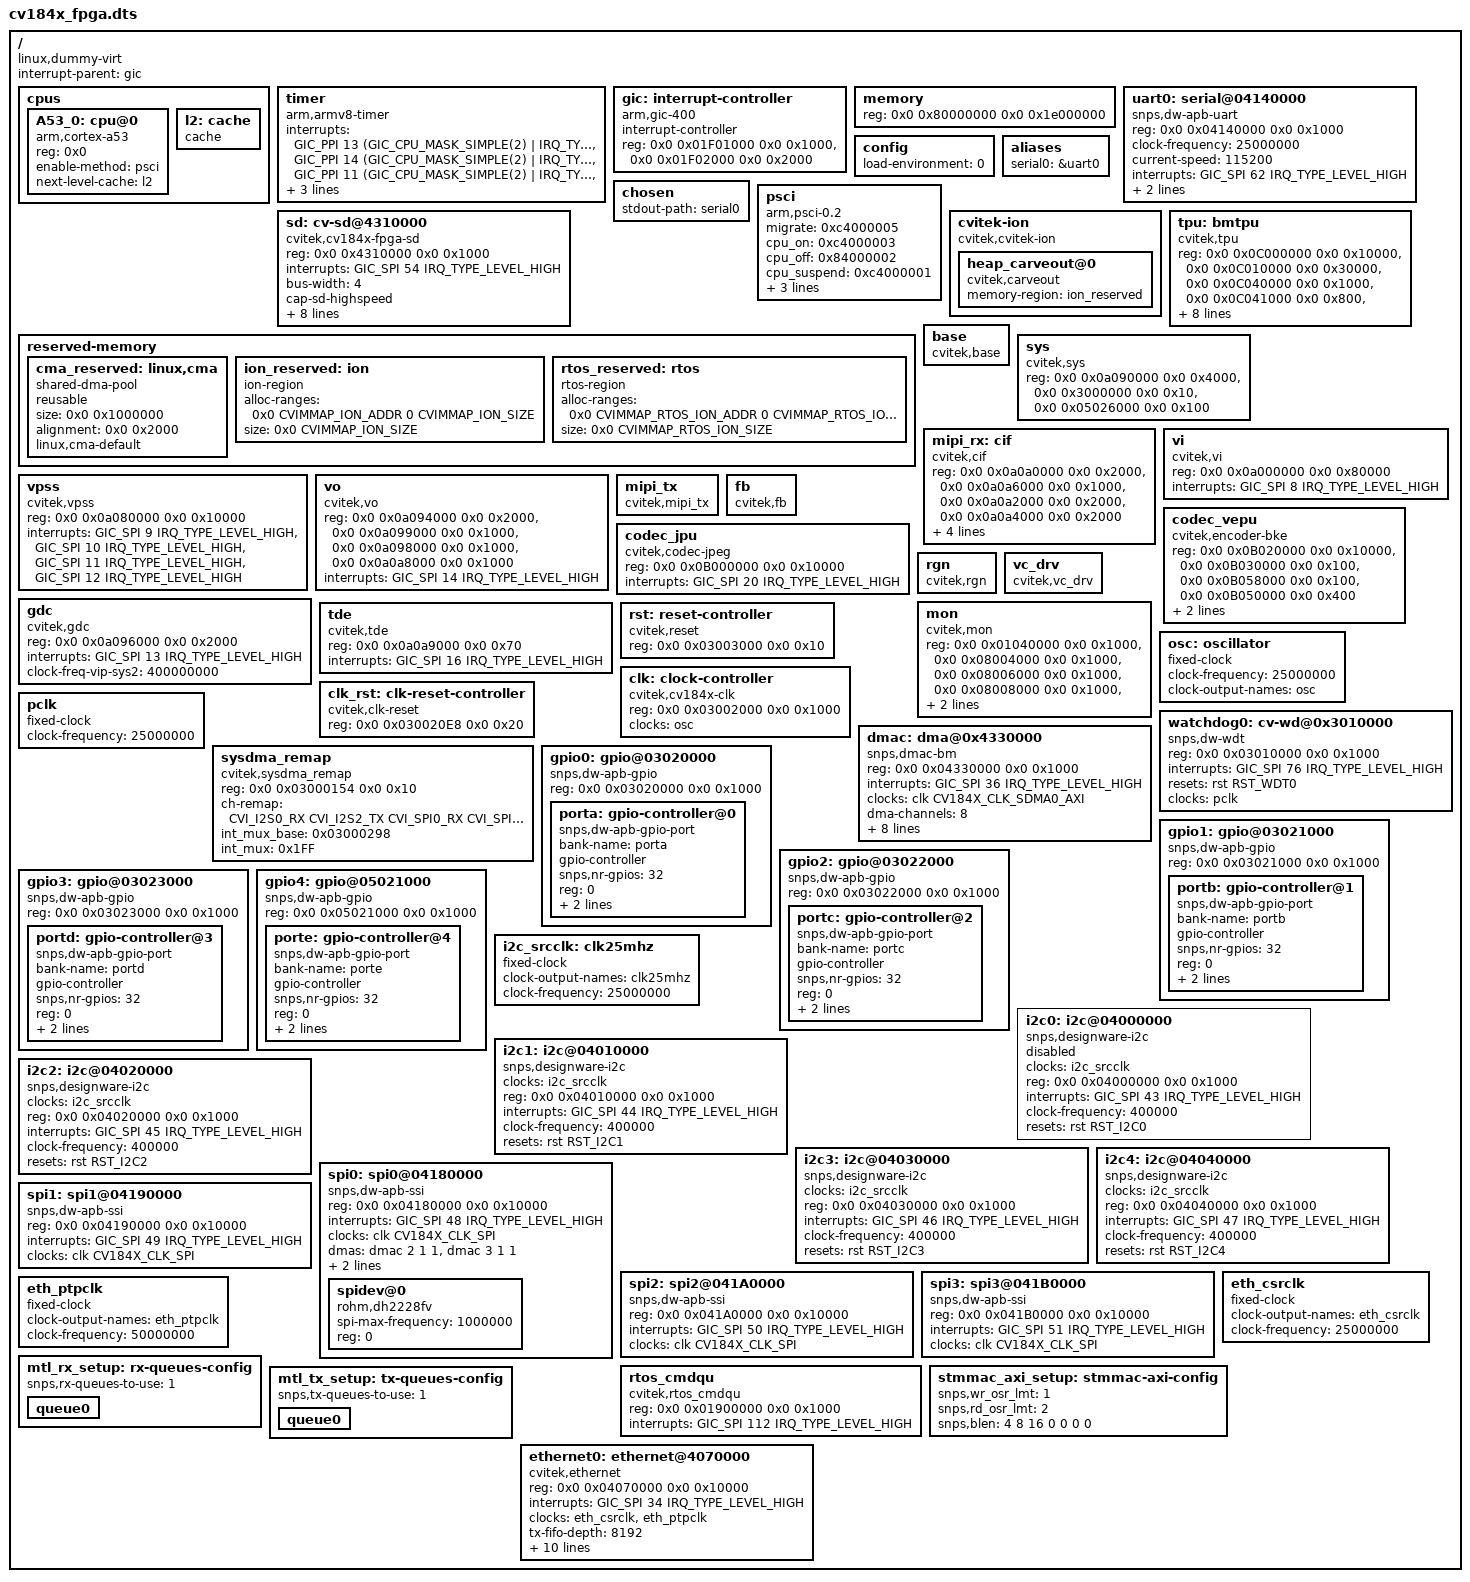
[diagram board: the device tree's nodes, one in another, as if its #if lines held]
#include <dt-bindings/interrupt-controller/arm-gic.h>
#include <dt-bindings/gpio/gpio.h>
#include <dt-bindings/reset/cv184x-resets.h>
#include <dt-bindings/clock/cv184x-clock.h>
//#include <dt-bindings/sound/cv1835-audio.h>
#include <dt-bindings/dma/cv184x-dmamap.h>
#include "cvi_board_memmap.h"
/dts-v1/;

/memreserve/	0x80000000 0x00000000000080000; // ATF BL31 + BL32
#if CVIMMAP_RTOS_SYS_TOTAL_SIZE > 0
/memreserve/	CVIMMAP_FSBL_C906L_START_ADDR CVIMMAP_RTOS_SYS_TOTAL_SIZE;
#endif
/ {
	compatible = "linux,dummy-virt";
	#size-cells = <0x2>;
	#address-cells = <0x2>;
	interrupt-parent = <&gic>;

	cpus {
		#size-cells = <0x0>;
		#address-cells = <0x1>;

		A53_0: cpu@0 {
			reg = <0x0>;
			enable-method = "psci";
			compatible = "arm,cortex-a53";
			device_type = "cpu";
			next-level-cache = <&l2>;
		};

		l2: cache {
			compatible = "cache";
		};
	};

	timer {
		interrupts = <GIC_PPI 13 (GIC_CPU_MASK_SIMPLE(2) | IRQ_TYPE_LEVEL_LOW)>,
			<GIC_PPI 14 (GIC_CPU_MASK_SIMPLE(2) | IRQ_TYPE_LEVEL_LOW)>,
			<GIC_PPI 11 (GIC_CPU_MASK_SIMPLE(2) | IRQ_TYPE_LEVEL_LOW)>,
			<GIC_PPI 10 (GIC_CPU_MASK_SIMPLE(2) | IRQ_TYPE_LEVEL_LOW)>;
		always-on;
		clock-frequency = <25000000>;
		compatible = "arm,armv8-timer";
	};

	gic: interrupt-controller {
		compatible = "arm,gic-400";
		ranges;
		#size-cells = <0x2>;
		#address-cells = <0x2>;
		interrupt-controller;
		#interrupt-cells = <0x3>;
		reg = <0x0 0x01F01000 0x0 0x1000>,
		      <0x0 0x01F02000 0x0 0x2000>;
	};

	memory {
		reg = <0x0 0x80000000 0x0 0x1e000000>;
		device_type = "memory";
	};

	uart0: serial@04140000 {
		compatible = "snps,dw-apb-uart";
		reg = <0x0 0x04140000 0x0 0x1000>;
		clock-frequency = <25000000>;
		current-speed = <115200>;
		interrupts = <GIC_SPI 62 IRQ_TYPE_LEVEL_HIGH>;
		reg-shift = <2>;
		reg-io-width = <4>;
	};

	config {
		load-environment = <0>;
	};

	aliases {
		serial0 = &uart0;
	};

	chosen {
		stdout-path = "serial0"; // "serial0:115200n8", no arguments means no re-initialization
	};

	psci {
		migrate = <0xc4000005>;
		cpu_on = <0xc4000003>;
		cpu_off = <0x84000002>;
		cpu_suspend = <0xc4000001>;
		sys_poweroff = <0x84000008>;
		sys_reset = <0x84000009>;
		method = "smc";
		compatible = "arm,psci-0.2", "arm,psci";
	};

	sd:cv-sd@4310000 {
		compatible = "cvitek,cv184x-fpga-sd";
		reg = <0x0 0x4310000 0x0 0x1000>;
		reg-names = "core_mem";
		interrupts = <GIC_SPI 54 IRQ_TYPE_LEVEL_HIGH>;
		bus-width = <4>;
		cap-sd-highspeed;
		src-frequency = <25000000>;
		min-frequency = <200000>;
		max-frequency = <4000000>;
		no-sdio;
		no-mmc;
		no-1-8-v;
		64_addressing;
		reset_tx_rx_phy;
		reset-names = "sdhci";
	};

	cvitek-ion {
		compatible = "cvitek,cvitek-ion";

		heap_carveout@0 {
			compatible = "cvitek,carveout";
			memory-region = <&ion_reserved>;
		};
	};

	reserved-memory {
		#address-cells = <0x2>;
		#size-cells = <0x2>;
		ranges;

		cma_reserved: linux,cma {
			compatible = "shared-dma-pool";
			reusable;
			size = <0x0 0x1000000>; // 16MB
			alignment = <0x0 0x2000>; // 8KB
			linux,cma-default;
		};

		ion_reserved: ion {
			compatible = "ion-region";
			alloc-ranges = <0x0 CVIMMAP_ION_ADDR 0 CVIMMAP_ION_SIZE>;
			size = <0x0 CVIMMAP_ION_SIZE>;
		};
#if CVIMMAP_RTOS_SYS_TOTAL_SIZE > 0
		rtos_reserved: rtos {
			compatible = "rtos-region";
			alloc-ranges = <0x0 CVIMMAP_RTOS_ION_ADDR 0 CVIMMAP_RTOS_ION_SIZE>;
			size = <0x0 CVIMMAP_RTOS_ION_SIZE>;
		};
#endif
	};


	tpu: bmtpu {
		compatible = "cvitek,tpu";
		reg-names = "tpu_gdma", "tpu_sys","tpu_reg","tpu_smem","tpu_lmem";
		reg = <0x0 0x0C000000 0x0 0x10000>,
			<0x0 0x0C010000 0x0 0x30000>,
			<0x0 0x0C040000 0x0 0x1000>,
			<0x0 0x0C041000 0x0 0x800>,
			<0x0 0x0C080000 0x0 0x8000>;
		interrupts = <GIC_SPI 89 IRQ_TYPE_LEVEL_HIGH>,
			<GIC_SPI 90 IRQ_TYPE_LEVEL_HIGH>,
			<GIC_SPI 91 IRQ_TYPE_LEVEL_HIGH>,
			<GIC_SPI 92 IRQ_TYPE_LEVEL_HIGH>,
			<GIC_SPI 93 IRQ_TYPE_LEVEL_HIGH>,
			<GIC_SPI 94 IRQ_TYPE_LEVEL_HIGH>,
			<GIC_SPI 95 IRQ_TYPE_LEVEL_HIGH>;
	};

	base {
		compatible = "cvitek,base";
	};

	sys {
		compatible = "cvitek,sys";
		reg = <0x0 0x0a090000 0x0 0x4000>,
				<0x0 0x3000000 0x0 0x10>,
				<0x0 0x05026000 0x0 0x100>;
		reg-names = "vi_sys", "top_base", "rtc_base";
	};

	mipi_rx: cif {
		compatible = "cvitek,cif";
		reg = <0x0 0x0a0a0000 0x0 0x2000>, <0x0 0x0a0a6000 0x0 0x1000>,
		      <0x0 0x0a0a2000 0x0 0x2000>, <0x0 0x0a0a4000 0x0 0x2000>;
		reg-names = "csi_mac0", "csi_wrap0", "csi_mac1", "csi_mac2";
		interrupts = <GIC_SPI 5 IRQ_TYPE_LEVEL_HIGH>,
			     <GIC_SPI 6 IRQ_TYPE_LEVEL_HIGH>, <GIC_SPI 7 IRQ_TYPE_LEVEL_HIGH>;
		interrupt-names = "csi0", "csi1", "csi2";
		snsr-reset = <&porta 2 GPIO_ACTIVE_LOW>;
	};

	vi {
		compatible = "cvitek,vi";
		reg = <0x0 0x0a000000 0x0 0x80000>;
		interrupts = <GIC_SPI 8 IRQ_TYPE_LEVEL_HIGH>;
		interrupt-names = "isp";
	};

	vpss {
		compatible = "cvitek,vpss";
		reg = <0x0 0x0a080000 0x0 0x10000>;
		reg-names = "vpss";
		interrupts = <GIC_SPI 9 IRQ_TYPE_LEVEL_HIGH>,
					<GIC_SPI 10 IRQ_TYPE_LEVEL_HIGH>,
					<GIC_SPI 11 IRQ_TYPE_LEVEL_HIGH>,
					<GIC_SPI 12 IRQ_TYPE_LEVEL_HIGH>;
		interrupt-names = "vpss_v0","vpss_v1","vpss_v2","vpss_v3";
	};

	vo {
		compatible = "cvitek,vo";
		reg =   <0x0 0x0a094000 0x0 0x2000>,
			<0x0 0x0a099000 0x0 0x1000>,
			<0x0 0x0a098000 0x0 0x1000>,
			<0x0 0x0a0a8000 0x0 0x1000>;
		reg-names = "disp", "dsi_mac", "dsi_phy", "vo_mac";

		interrupts = <GIC_SPI 14 IRQ_TYPE_LEVEL_HIGH>;
		interrupt-names = "disp";
	};

	mipi_tx {
		compatible = "cvitek,mipi_tx";
	};

	fb {
		compatible = "cvitek,fb";
	};

	codec_vepu {
		compatible = "cvitek,encoder-bke";
		reg = <0x0 0x0B020000 0x0 0x10000>,<0x0 0x0B030000 0x0 0x100>,
				<0x0 0x0B058000 0x0 0x100>,<0x0 0x0B050000 0x0 0x400>;
		reg-names = "vepu","vc_ctrl","vc_sbm","vc_addr_remap";
		interrupts = <GIC_SPI 19 IRQ_TYPE_LEVEL_HIGH>,
					<GIC_SPI 21 IRQ_TYPE_LEVEL_HIGH>;
		interrupt-names = "vepu_irq","sbm_irq";
	};

	codec_jpu {
		compatible = "cvitek,codec-jpeg";
		reg = <0x0 0x0B000000 0x0 0x10000>;
		reg-names = "jpeg_ctrl";
		interrupts = <GIC_SPI 20 IRQ_TYPE_LEVEL_HIGH>;
		interrupt-names = "jpeg_irq";
	};

	rgn {
		compatible = "cvitek,rgn";
	};

	vc_drv {
		compatible = "cvitek,vc_drv";
	};

	gdc {
		compatible = "cvitek,gdc";
		reg = <0x0 0x0a096000 0x0 0x2000>;
		reg-names = "ldc0";
		interrupts = <GIC_SPI 13 IRQ_TYPE_LEVEL_HIGH>;
		interrupt-names = "ldc0";
		clock-names = "clk_ldc0";
		clock-freq-vip-sys2 = <400000000>;
	};

	tde {
		compatible = "cvitek,tde";
		reg = <0x0 0x0a0a9000 0x0 0x70>;
		reg-names = "tde";
		interrupts = <GIC_SPI 16 IRQ_TYPE_LEVEL_HIGH>;
		interrupt-names = "tde";
	};


	mon {
		compatible = "cvitek,mon";
		reg-names = "pcmon", "ddr_ctrl", "ddr_phyd", "ddr_aximon", "ddr_top";
		reg = <0x0 0x01040000 0x0 0x1000>,
		    <0x0 0x08004000 0x0 0x1000>,
			<0x0 0x08006000 0x0 0x1000>,
			<0x0 0x08008000 0x0 0x1000>,
			<0x0 0x0800A000 0x0 0x1000>;
		interrupts = <GIC_SPI 22 IRQ_TYPE_EDGE_RISING>;
	};


	rst: reset-controller {
		#reset-cells = <1>;
		compatible = "cvitek,reset";
		reg = <0x0 0x03003000 0x0 0x10>;
	};

	osc: oscillator {
		#clock-cells = <0>;
		compatible = "fixed-clock";
		clock-frequency = <25000000>;
		clock-output-names = "osc";
	};

	clk: clock-controller {
		compatible = "cvitek,cv184x-clk";
		reg = <0x0 0x03002000 0x0 0x1000>;
		clocks = <&osc>;
		#clock-cells = <1>;
	};

	clk_rst: clk-reset-controller {
		#reset-cells = <1>;
		compatible = "cvitek,clk-reset";
		reg = <0x0 0x030020E8 0x0 0x20>;
	};

	pclk: pclk {
		#clock-cells = <0>;
		compatible = "fixed-clock";
		clock-frequency = <25000000>;
	};

	watchdog0: cv-wd@0x3010000 {
		compatible = "snps,dw-wdt";
		reg = <0x0 0x03010000 0x0 0x1000>;
		interrupts = <GIC_SPI 76 IRQ_TYPE_LEVEL_HIGH>;
		resets = <&rst RST_WDT0>;
		clocks = <&pclk>;
	};

	sysdma_remap {
		compatible = "cvitek,sysdma_remap";
		reg = <0x0 0x03000154 0x0 0x10>;
		ch-remap = <CVI_I2S0_RX CVI_I2S2_TX CVI_SPI0_RX CVI_SPI0_TX
					CVI_SPI_NAND CVI_SPI_NAND CVI_I2S2_RX CVI_I2S3_TX>;
		int_mux_base = <0x03000298>;
		int_mux = <0x1FF>; /* enable bit [0..8] for CPU0(CA53) */
	};

	dmac: dma@0x4330000 {
		compatible = "snps,dmac-bm";
		reg = <0x0 0x04330000 0x0 0x1000>;
		interrupts = <GIC_SPI 36 IRQ_TYPE_LEVEL_HIGH>;
		clock-names = "clk_sdma0_axi";
		clocks = <&clk CV184X_CLK_SDMA0_AXI>;

		dma-channels = /bits/ 8 <8>;
		#dma-cells = <3>;
		dma-requests = /bits/ 8 <16>;
		chan_allocation_order = /bits/ 8 <0>;
		chan_priority = /bits/ 8 <1>;
		block_size = <1024>;
		dma-masters = /bits/ 8 <2>;
		data-width = <4 4>; /* bytes */
		axi_tr_width = <4>; /* bytes */
		block-ts = <15>;
	};

	gpio0: gpio@03020000 {
		compatible = "snps,dw-apb-gpio";
		reg = <0x0 0x03020000 0x0 0x1000>;
		#address-cells = <1>;
		#size-cells = <0>;

		porta: gpio-controller@0 {
			compatible = "snps,dw-apb-gpio-port";
			bank-name = "porta";
			gpio-controller;
			#gpio-cells = <2>;
			snps,nr-gpios = <32>;
			reg = <0>;
			interrupt-controller;
			interrupts = <GIC_SPI 79 IRQ_TYPE_LEVEL_HIGH>;
		};
	};

	gpio1: gpio@03021000 {
		compatible = "snps,dw-apb-gpio";
		reg = <0x0 0x03021000 0x0 0x1000>;
		#address-cells = <1>;
		#size-cells = <0>;

		portb: gpio-controller@1 {
			compatible = "snps,dw-apb-gpio-port";
			bank-name = "portb";
			gpio-controller;
			#gpio-cells = <2>;
			snps,nr-gpios = <32>;
			reg = <0>;
			interrupt-controller;
			interrupts = <GIC_SPI 80 IRQ_TYPE_LEVEL_HIGH>;
		};
	};

	gpio2: gpio@03022000 {
		compatible = "snps,dw-apb-gpio";
		reg = <0x0 0x03022000 0x0 0x1000>;
		#address-cells = <1>;
		#size-cells = <0>;

		portc: gpio-controller@2 {
			compatible = "snps,dw-apb-gpio-port";
			bank-name = "portc";
			gpio-controller;
			#gpio-cells = <2>;
			snps,nr-gpios = <32>;
			reg = <0>;
			interrupt-controller;
			interrupts = <GIC_SPI 81 IRQ_TYPE_LEVEL_HIGH>;
		};
	};

	gpio3: gpio@03023000 {
		compatible = "snps,dw-apb-gpio";
		reg = <0x0 0x03023000 0x0 0x1000>;
		#address-cells = <1>;
		#size-cells = <0>;

		portd: gpio-controller@3 {
			compatible = "snps,dw-apb-gpio-port";
			bank-name = "portd";
			gpio-controller;
			#gpio-cells = <2>;
			snps,nr-gpios = <32>;
			reg = <0>;
			interrupt-controller;
			interrupts = <GIC_SPI 82 IRQ_TYPE_LEVEL_HIGH>;
		};
	};

	gpio4: gpio@05021000 {
		compatible = "snps,dw-apb-gpio";
		reg = <0x0 0x05021000 0x0 0x1000>;
		#address-cells = <1>;
		#size-cells = <0>;

		porte: gpio-controller@4 {
			compatible = "snps,dw-apb-gpio-port";
			bank-name = "porte";
			gpio-controller;
			#gpio-cells = <2>;
			snps,nr-gpios = <32>;
			reg = <0>;
			interrupt-controller;
			interrupts = <GIC_SPI 29 IRQ_TYPE_LEVEL_HIGH>;
		};
	};

	i2c_srcclk: clk25mhz {
		clock-output-names = "clk25mhz";
		clock-frequency = <25000000>;
		#clock-cells = <0x0>;
		compatible = "fixed-clock";
	};


	i2c0: i2c@04000000 {
		compatible = "snps,designware-i2c";
		clocks = <&i2c_srcclk>;
		reg = <0x0 0x04000000 0x0 0x1000>;
		interrupts = <GIC_SPI 43 IRQ_TYPE_LEVEL_HIGH>;
		clock-frequency = <400000>;

		#size-cells = <0x0>;
		#address-cells = <0x1>;
		resets = <&rst RST_I2C0>;
		reset-names = "i2c0";
		status = "disabled";
	};

	i2c1: i2c@04010000 {
		compatible = "snps,designware-i2c";
		clocks = <&i2c_srcclk>;
		reg = <0x0 0x04010000 0x0 0x1000>;
		interrupts = <GIC_SPI 44 IRQ_TYPE_LEVEL_HIGH>;
		clock-frequency = <400000>;

		#size-cells = <0x0>;
		#address-cells = <0x1>;
		resets = <&rst RST_I2C1>;
		reset-names = "i2c1";
	};

	i2c2: i2c@04020000 {
		compatible = "snps,designware-i2c";
		clocks = <&i2c_srcclk>;
		reg = <0x0 0x04020000 0x0 0x1000>;
		interrupts = <GIC_SPI 45 IRQ_TYPE_LEVEL_HIGH>;
		clock-frequency = <400000>;
		resets = <&rst RST_I2C2>;
		reset-names = "i2c2";
	};

	i2c3: i2c@04030000 {
		compatible = "snps,designware-i2c";
		clocks = <&i2c_srcclk>;
		reg = <0x0 0x04030000 0x0 0x1000>;
		interrupts = <GIC_SPI 46 IRQ_TYPE_LEVEL_HIGH>;
		clock-frequency = <400000>;

		#size-cells = <0x0>;
		#address-cells = <0x1>;
		resets = <&rst RST_I2C3>;
		reset-names = "i2c3";
	};

	i2c4: i2c@04040000 {
		compatible = "snps,designware-i2c";
		clocks = <&i2c_srcclk>;
		reg = <0x0 0x04040000 0x0 0x1000>;
		interrupts = <GIC_SPI 47 IRQ_TYPE_LEVEL_HIGH>;
		clock-frequency = <400000>;
		resets = <&rst RST_I2C4>;
		reset-names = "i2c4";
	};

	spi0:spi0@04180000 {
		compatible = "snps,dw-apb-ssi";
		reg = <0x0 0x04180000 0x0 0x10000>;
		interrupts = <GIC_SPI 48 IRQ_TYPE_LEVEL_HIGH>;
		clocks = <&clk CV184X_CLK_SPI>;
		#address-cells = <1>;
		#size-cells = <0>;
		dmas = <&dmac 2 1 1
			&dmac 3 1 1>;
		dma-names = "rx", "tx";
		capability = "txrx";
		status = "okay";
		num-cs = <1>;
		spidev@0 {
			compatible = "rohm,dh2228fv";
			spi-max-frequency = <1000000>;
			reg = <0>;
		};
	};

	spi1:spi1@04190000 {
		compatible = "snps,dw-apb-ssi";
		reg = <0x0 0x04190000 0x0 0x10000>;
		interrupts = <GIC_SPI 49 IRQ_TYPE_LEVEL_HIGH>;
		clocks = <&clk CV184X_CLK_SPI>;
		#address-cells = <1>;
		#size-cells = <0>;
	};

	spi2:spi2@041A0000 {
		compatible = "snps,dw-apb-ssi";
		reg = <0x0 0x041A0000 0x0 0x10000>;
		interrupts = <GIC_SPI 50 IRQ_TYPE_LEVEL_HIGH>;
		clocks = <&clk CV184X_CLK_SPI>;
		#address-cells = <1>;
		#size-cells = <0>;
	};

	spi3:spi3@041B0000 {
		compatible = "snps,dw-apb-ssi";
		reg = <0x0 0x041B0000 0x0 0x10000>;
		interrupts = <GIC_SPI 51 IRQ_TYPE_LEVEL_HIGH>;
		clocks = <&clk CV184X_CLK_SPI>;
		#address-cells = <1>;
		#size-cells = <0>;
	};
#if CVIMMAP_RTOS_SYS_TOTAL_SIZE > 0
	rtos_cmdqu {
		compatible = "cvitek,rtos_cmdqu";
		reg = <0x0 0x01900000 0x0 0x1000>;
		reg-names = "mailbox";
		interrupts = <GIC_SPI 112 IRQ_TYPE_LEVEL_HIGH>;
		interrupt-names = "mailbox";
	};
#endif



#if 0
	pmu_a53 {
		compatible = "arm,cortex-a53-pmu";
		interrupts = <GIC_SPI 86 IRQ_TYPE_LEVEL_HIGH>,
			     <GIC_SPI 87 IRQ_TYPE_LEVEL_HIGH>;
		interrupt-affinity = <&A53_0>;
	};

	rst: reset-controller {
		#reset-cells = <1>;
		compatible = "cvitek,reset";
		reg = <0x0 0x03003000 0x0 0x10>;
	};

	osc: oscillator {
		#clock-cells = <0>;
		compatible = "fixed-clock";
		clock-frequency = <25000000>;
		clock-output-names = "osc";
	};

	clk: clock-controller {
		compatible = "cvitek,cv184x-clk";
		reg = <0x0 0x03002000 0x0 0x1000>;
		clocks = <&osc>;
		#clock-cells = <1>;
	};

	tpu {
		compatible = "cvitek,tpu";
		reg-names = "tdma", "tiu";
		reg = <0x0 0x0C100000 0x0 0x1000>,
			  <0x0 0x0C101000 0x0 0x1000>;
		interrupts = <GIC_SPI 59 IRQ_TYPE_EDGE_RISING>,
			     <GIC_SPI 60 IRQ_TYPE_EDGE_RISING>;
	};

	mon {
		compatible = "cvitek,mon";
		reg-names = "pcmon", "ddr_ctrl", "ddr_phyd", "ddr_aximon", "ddr_top";
		reg = <0x0 0x01040000 0x0 0x1000>,
					<0x0 0x08004000 0x0 0x1000>,
					<0x0 0x08006000 0x0 0x1000>,
					<0x0 0x08008000 0x0 0x1000>,
					<0x0 0x0800A000 0x0 0x1000>;
		interrupts = <GIC_SPI 77 IRQ_TYPE_EDGE_RISING>;
	};


	cviaudio_core {
		compatible = "cvitek,audio";
	};

	sysdma_remap {
		compatible = "cvitek,sysdma_remap";
		reg = <0x0 0x03000154 0x0 0x10>;
		ch-remap = <CVI_I2S0_RX CVI_I2S2_TX CVI_I2S1_RX CVI_I2S1_TX
					CVI_SPI_NAND CVI_SPI_NAND CVI_I2S2_RX CVI_I2S3_TX>;
		int_mux_base = <0x03000298>;
		int_mux = <0x1FF>; /* enable bit [0..8] for CPU0(CA53) */
	};

	dmac: dma@0x4330000 {
		compatible = "snps,dmac-bm";
		reg = <0x0 0x04330000 0x0 0x1000>;
		interrupts = <GIC_SPI 13 IRQ_TYPE_LEVEL_HIGH>;
		clock-names = "clk_sdma0_axi";
		clocks = <&clk CV184X_CLK_SDMA0_AXI>;

		dma-channels = /bits/ 8 <8>;
		#dma-cells = <3>;
		dma-requests = /bits/ 8 <16>;
		chan_allocation_order = /bits/ 8 <0>;
		chan_priority = /bits/ 8 <1>;
		block_size = <1024>;
		dma-masters = /bits/ 8 <2>;
		data-width = <4 4>; /* bytes */
		axi_tr_width = <4>; /* bytes */
		block-ts = <15>;
	};

	watchdog0: cv-wd@0x3010000 {
		compatible = "snps,dw-wdt";
		reg = <0x0 0x03010000 0x0 0x1000>;
		interrupts = <GIC_SPI 42 IRQ_TYPE_LEVEL_HIGH>;
		resets = <&rst RST_WDT0>;
		clocks = <&pclk>;
	};

	pclk: pclk {
		#clock-cells = <0>;
		compatible = "fixed-clock";
		clock-frequency = <25000000>;
	};


	usb: usb@04340000 {
		compatible = "cvitek,cv182x-usb";
		reg = <0x0 0x04340000 0x0 0x10000>, <0x0 0x03006000 0x0 0x58>;
		interrupts = <GIC_SPI 14 IRQ_TYPE_LEVEL_HIGH>;
		dr_mode = "otg";
		g-use-dma;
		g-rx-fifo-size = <536>;
		g-np-tx-fifo-size = <32>;
		g-tx-fifo-size = <768 512 512 384 128 128>;
#if 0
		clocks = <&clk CV184X_CLK_AXI4_USB>,
				<&clk CV184X_CLK_APB_USB>,
				<&clk CV184X_CLK_125M_USB>,
				<&clk CV184X_CLK_33K_USB>,
				<&clk CV184X_CLK_12M_USB>;
		clock-names = "clk_axi", "clk_apb", "clk_125m", "clk_33k", "clk_12m";
		vbus-gpio = <&portb 6 0>;
#endif
		status = "okay";
	};
#endif
	eth_csrclk: eth_csrclk {
		clock-output-names = "eth_csrclk";
		clock-frequency = <25000000>;
		#clock-cells = <0x0>;
		compatible = "fixed-clock";
	};

	eth_ptpclk: eth_ptpclk {
		clock-output-names = "eth_ptpclk";
		clock-frequency = <50000000>;
		#clock-cells = <0x0>;
		compatible = "fixed-clock";
	};

	stmmac_axi_setup: stmmac-axi-config {
		snps,wr_osr_lmt = <1>;
		snps,rd_osr_lmt = <2>;
		snps,blen = <4 8 16 0 0 0 0>;
	};

	mtl_rx_setup: rx-queues-config {
		snps,rx-queues-to-use = <1>;
		queue0 {};
	};

	mtl_tx_setup: tx-queues-config {
		snps,tx-queues-to-use = <1>;
		queue0 {};
	};

	ethernet0: ethernet@4070000 {
		compatible = "cvitek,ethernet";
		reg = <0x0 0x04070000 0x0 0x10000>;
		interrupt-names = "macirq";
		interrupts = <GIC_SPI 34 IRQ_TYPE_LEVEL_HIGH>;
		clock-names = "stmmaceth", "ptp_ref";
		clocks = <&eth_csrclk>, <&eth_ptpclk>;
		//phy-reset-gpios = <&porta 26 0>;
		tx-fifo-depth = <8192>;
		rx-fifo-depth = <8192>;
		/* no hash filter and perfect filter support */
		snps,multicast-filter-bins = <0>;
		snps,perfect-filter-entries = <1>;
		snps,txpbl = <8>;
		snps,rxpbl = <8>;
		snps,aal;

		snps,axi-config = <&stmmac_axi_setup>;
		snps,mtl-rx-config = <&mtl_rx_setup>;
		snps,mtl-tx-config = <&mtl_tx_setup>;

		phy-mode = "rmii";
	};

#if 0
	gpio0: gpio@03020000 {
		compatible = "snps,dw-apb-gpio";
		reg = <0x0 0x03020000 0x0 0x1000>;
		#address-cells = <1>;
		#size-cells = <0>;

		porta: gpio-controller@0 {
			compatible = "snps,dw-apb-gpio-port";
			bank-name = "porta";
			gpio-controller;
			#gpio-cells = <2>;
			snps,nr-gpios = <32>;
			reg = <0>;
			interrupt-controller;
			interrupts = <GIC_SPI 44 IRQ_TYPE_LEVEL_HIGH>;
		};
	};

	gpio3: gpio@03023000 {
		compatible = "snps,dw-apb-gpio";
		reg = <0x0 0x03023000 0x0 0x1000>;
		#address-cells = <1>;
		#size-cells = <0>;

		portd: gpio-controller@2 {
			compatible = "snps,dw-apb-gpio-port";
			bank-name = "portd";
			gpio-controller;
			#gpio-cells = <2>;
			snps,nr-gpios = <12>;
			reg = <0>;
			interrupt-controller;
			interrupts = <GIC_SPI 47 IRQ_TYPE_LEVEL_HIGH>;
		};
	};

	i2c_srcclk: clk25mhz {
		clock-output-names = "clk25mhz";
		clock-frequency = <25000000>;
		#clock-cells = <0x0>;
		compatible = "fixed-clock";
	};

	audio_clock: audio_clock {
		compatible = "fixed-clock";
		#clock-cells = <0>;
#if 0
		clock-frequency = <12288000>;
#else
		clock-frequency = <24576000>;
#endif
		};

	emmc:cv-emmc@4300000 {
			compatible = "cvitek,cv184x-fpga-emmc";
			reg = <0x0 0x4300000 0x0 0x1000>;
			reg-names = "core_mem";
			interrupts = <GIC_SPI 18 IRQ_TYPE_LEVEL_HIGH>;
			bus-width = <4>;
			non-removable;
			max-frequency = <12000000>;
			no-sdio;
			no-sd;
	};

	sd:cv-sd@4310000 {
			compatible = "cvitek,cv184x-fpga-sd";
			reg = <0x0 0x4310000 0x0 0x1000>;
			reg-names = "core_mem";
			interrupts = <GIC_SPI 20 IRQ_TYPE_LEVEL_HIGH>;
			bus-width = <4>;
			max-frequency = <12000000>;
			no-sdio;
			no-mmc;
	};

	i2c0: i2c@04000000 {
		compatible = "snps,designware-i2c";
		clocks = <&i2c_srcclk>;
		reg = <0x0 0x04000000 0x0 0x1000>;
		interrupts = <GIC_SPI 33 IRQ_TYPE_LEVEL_HIGH>;
		clock-frequency = <400000>;

		#size-cells = <0x0>;
		#address-cells = <0x1>;
		resets = <&rst RST_I2C0>;
		reset-names = "i2c0";
	};

	i2c1: i2c@04010000 {
		compatible = "snps,designware-i2c";
		clocks = <&clk CV184X_CLK_I2C>;
		reg = <0x0 0x04010000 0x0 0x1000>;
		interrupts = <GIC_SPI 34 IRQ_TYPE_LEVEL_HIGH>;
		clock-frequency = <400000>;

		#size-cells = <0x0>;
		#address-cells = <0x1>;
		resets = <&rst RST_I2C1>;
		reset-names = "i2c1";
	};

	i2c2: i2c@04020000 {
		compatible = "snps,designware-i2c";
		clocks = <&clk CV184X_CLK_I2C>;
		reg = <0x0 0x04020000 0x0 0x1000>;
		interrupts = <GIC_SPI 35 IRQ_TYPE_LEVEL_HIGH>;
		clock-frequency = <400000>;
		resets = <&rst RST_I2C2>;
		reset-names = "i2c2";
	};

	i2c3: i2c@04030000 {
		compatible = "snps,designware-i2c";
		clocks = <&i2c_srcclk>;
		reg = <0x0 0x04030000 0x0 0x1000>;
		interrupts = <GIC_SPI 36 IRQ_TYPE_LEVEL_HIGH>;
		clock-frequency = <400000>;

		#size-cells = <0x0>;
		#address-cells = <0x1>;
		resets = <&rst RST_I2C3>;
		reset-names = "i2c3";
	};

	i2c4: i2c@04040000 {
		compatible = "snps,designware-i2c";
		clocks = <&clk CV184X_CLK_I2C>;
		reg = <0x0 0x04040000 0x0 0x1000>;
		interrupts = <GIC_SPI 37 IRQ_TYPE_LEVEL_HIGH>;
		clock-frequency = <400000>;
		resets = <&rst RST_I2C4>;
		reset-names = "i2c4";
	};

	spi0:spi0@04180000 {
		compatible = "snps,dw-apb-ssi";
		reg = <0x0 0x04180000 0x0 0x10000>;
		interrupts = <GIC_SPI 38 IRQ_TYPE_LEVEL_HIGH>;
		clocks = <&clk CV184X_CLK_SPI>;
		#address-cells = <1>;
		#size-cells = <0>;
	};

	spi1:spi1@04190000 {
		compatible = "snps,dw-apb-ssi";
		reg = <0x0 0x04190000 0x0 0x10000>;
		interrupts = <GIC_SPI 39 IRQ_TYPE_LEVEL_HIGH>;
		clocks = <&clk CV184X_CLK_SPI>;
		#address-cells = <1>;
		#size-cells = <0>;
	};

	spi2:spi2@041A0000 {
		compatible = "snps,dw-apb-ssi";
		reg = <0x0 0x041A0000 0x0 0x10000>;
		interrupts = <GIC_SPI 40 IRQ_TYPE_LEVEL_HIGH>;
		clocks = <&clk CV184X_CLK_SPI>;
		#address-cells = <1>;
		#size-cells = <0>;
	};

	spi3:spi3@041B0000 {
		compatible = "snps,dw-apb-ssi";
		reg = <0x0 0x041B0000 0x0 0x10000>;
		interrupts = <GIC_SPI 41 IRQ_TYPE_LEVEL_HIGH>;
		clocks = <&clk CV184X_CLK_SPI>;
		#address-cells = <1>;
		#size-cells = <0>;
#if 0
		dmas = <&dmac 2 1 1
			&dmac 3 1 1>;
		dma-names = "rx", "tx";
		capability = "txrx";
#endif
	};

	i2s_mclk: i2s_mclk {
		clock-output-names = "i2s_mclk";
		clock-frequency = <24576000>;
		#clock-cells = <0x0>;
		compatible = "fixed-clock";
	};

	i2s_subsys {
		compatible = "cvitek,i2s_tdm_subsys";
		reg = <0x0 0x04108000 0x0 0x100>;
		clocks = <&i2s_mclk>, <&clk CV184X_CLK_A0PLL>,
			<&clk CV184X_CLK_SDMA_AUD0>, <&clk CV184X_CLK_SDMA_AUD1>,
			<&clk CV184X_CLK_SDMA_AUD2>, <&clk CV184X_CLK_SDMA_AUD3>;
		clock-names = "i2sclk", "clk_a0pll",
			"clk_sdma_aud0", "clk_sdma_aud1",
			"clk_sdma_aud2", "clk_sdma_aud3";
	};

	i2s0: i2s@4100000 {
		compatible = "cvitek,cvitek-i2s";
		reg = <0x0 0x04100000 0x0 0x2000>;
		clocks = <&i2s_mclk 0>;
		clock-names = "i2sclk";
		dev-id = <0>;
		#sound-dai-cells = <0>;
		dmas = <&dmac 0 1 1>; /* read channel */
		dma-names = "rx";
		capability = "rx"; /* I2S0 connect to internal ADC as RX */
		mclk_out = "false";
	};

	i2s1: i2s@4110000 {
		compatible = "cvitek,cvitek-i2s";
		reg = <0x0 0x04110000 0x0 0x2000>;
		clocks = <&i2s_mclk 0>;
		clock-names = "i2sclk";
		dev-id = <1>;
		#sound-dai-cells = <0>;
		dmas = <&dmac 2 1 1 /* read channel */
			&dmac 3 1 1>; /* write channel */
		dma-names = "rx", "tx";
		capability = "txrx";
		mclk_out = "false";
	};

	i2s2: i2s@4120000 {
		compatible = "cvitek,cvitek-i2s";
		reg = <0x0 0x04120000 0x0 0x2000>;
		clocks = <&i2s_mclk 0>;
		clock-names = "i2sclk";
		dev-id = <2>;
		#sound-dai-cells = <0>;
		dmas = <&dmac 6 1 1 /* read channel */
			&dmac 1 1 1>; /* write channel */
		dma-names = "rx", "tx";
		capability = "txrx";
		mclk_out = "false";

	};

	i2s3: i2s@4130000 {
		compatible = "cvitek,cvitek-i2s";
		reg = <0x0 0x04130000 0x0 0x2000>;
		clocks = <&i2s_mclk 0>;
		clock-names = "i2sclk";
		dev-id = <3>;
		#sound-dai-cells = <0>;
		dmas = <&dmac 7 1 1>; /* write channel */
		dma-names = "tx";
		capability = "tx"; /* I2S3 connect to internal DAC as TX */
		mclk_out = "true";
	};

	adc: adc@300A100 {
		compatible = "cvitek,cvitek_adc";
		reg = <0x0 0x0300A100 0x0 0x100>;
		clocks = <&i2s_mclk 0>;
		clock-names = "i2sclk";
		clk_source = <0x04130000>; /* MCLK source is I2S3 */

		dev_id = <0>;
		dac_addr = <0x0300A000>;
		bind_i2s = <0>;
		sdma_clk_en = <0x3002004>;
		reset_cntl = <0x03003008>, <29>;	/* ip soft reset */
	};

	dac: dac@300A000 {
		compatible = "cvitek,cvitek_dac";
		reg = <0x0 0x0300A000 0x0 0x100>;
		clocks = <&i2s_mclk 0>;
		clock-names = "i2sclk";

		dev_id = <0>;
		bind_i2s = <3>;
		sdma_clk_en = <0x3002004>;
		reset_cntl = <0x03003008>, <27>;	/* ip soft reset */
	};

	pdm: pdm@41D0C00 {
		compatible = "cvitek,cvitek_pdm";
		reg = <0x0 0x041D0C00 0x0 0x100>;
		clocks = <&i2s_mclk 0>;
		clock-names = "i2sclk";
	};

	sound_adc {
		compatible = "cvitek,cvitek-card-adc";
		card_name = "adc_card";

		dai@0 {
			dai_name = "dai_codec_adc0";
			stream_name = "dai_record0";
			cpu_dai_name = "4100000.i2s";
			codec_dai_name = "300a100.adc";
			platform_name = "4100000.i2s";
			codec_name = "adc";
			stream_type = "capture";
			mode = "I2S";
			fmt = "IBNF";
			role = "slave";
			slot_no = <2>;
			//adc0:0300A100 - i2s0:04100000;
		};
#if 0
		dai@1 {
			dai_name = "dai_codec_pdm";
			stream_name = "dai_pdm";
			cpu_dai_name = "4110000.i2s";
			codec_dai_name = "41D0C00.pdm";
			platform_name = "4110000.i2s";
			codec_name = "pdm";
			stream_type = "capture";
			mode = "I2S";
			fmt = "IBNF";
			role = "slave";
			slot_no = <2>;
			status = "disabled";
			//pdm:041D0C00 - i2s1:04110000;
		};
#endif
	};

	sound_dac {
		compatible = "cvitek,cvitek-card-dac";
		card_name = "dac_card";

		dai@0 {
			dai_name = "dai_codec_dac0";
			stream_name = "dai_playback0";
			cpu_dai_name = "4130000.i2s";
			codec_dai_name = "300a000.dac";
			platform_name = "4130000.i2s";
			codec_name = "dac";
			stream_type = "playback";
			mode = "I2S";
			fmt = "IBNF";
			role = "master";
			slot_no = <2>;
		};
	};

	sound_ext {
		compatible = "cvitek,cvitek-ext";
		model = "cvitek";
		card_name = "ext_sound_card";
		status = "disabled";
		dai@0 {
			dai_name = "ext_record";
			stream_name = "record_stream";
			cpu_dai_name = "4110000.i2s";
			codec_dai_name = "dummy_codec";
			platform_name = "4110000.i2s";
			codec_name = "dummy_codec-aif";
			stream_type = "capture";
			mode = "I2S";
			fmt = "IBNF";
			role = "master";
			slot_no=<2>;
		};

		dai@1 {
			dai_name = "ext_playback";
			stream_name = "play_stream";
			cpu_dai_name = "4120000.i2s";
			codec_dai_name = "dummy_codec";
			platform_name = "4120000.i2s";
			codec_name = "dummy_codec-aif";
			stream_type = "playback";
			mode = "I2S";
			fmt = "IBNF";
			role = "master";
			slot_no=<2>;
		};
	};

	rtos_cmdqu {
		compatible = "cvitek,rtos_cmdqu";
		reg = <0x0 0x01900000 0x0 0x1000>;
		reg-names = "mailbox";
		interrupts = <GIC_SPI 85 IRQ_TYPE_LEVEL_HIGH>;
		interrupt-names = "mailbox";
	};

#endif
};

